# ESP32-S31 register map
Vendor: ESPRESSIF SYSTEMS (SHANGHAI) CO., LTD.; Series: ESP32 S-Series; File version: 1
CPU: RV32IMAFC r0p0, little endian, no MPU, FPU, 0 interrupt priority bits
Address unit: 32 bits
Registers are 32-bit, read-write, reset 0x0 unless marked. A register's access mark holds for its fields unless they carry their own. Offsets are from the block's base; [hi:lo] are bit positions; {n}, {i} and the like mark numbered series.

## LP_TOUCH_AON — LP_TOUCH_AON Peripheral
Base 0x20705000
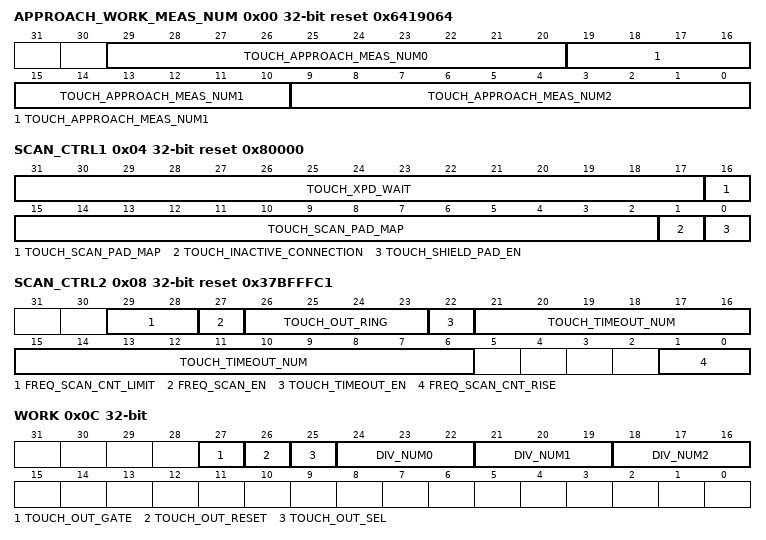
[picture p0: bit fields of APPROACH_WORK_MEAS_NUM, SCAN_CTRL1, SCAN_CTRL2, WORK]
0x00 APPROACH_WORK_MEAS_NUM reset 0x6419064 — need_des
  [29:20] TOUCH_APPROACH_MEAS_NUM0 — need_des
  [19:10] TOUCH_APPROACH_MEAS_NUM1 — need_des
  [9:0] TOUCH_APPROACH_MEAS_NUM2 — need_des
0x04 SCAN_CTRL1 reset 0x80000 — need_des
  [31:17] TOUCH_XPD_WAIT — need_des
  [16:2] TOUCH_SCAN_PAD_MAP — need_des
  [1] TOUCH_INACTIVE_CONNECTION — need_des
  [0] TOUCH_SHIELD_PAD_EN — need_des
0x08 SCAN_CTRL2 reset 0x37BFFFC1 — need_des
  [29:28] FREQ_SCAN_CNT_LIMIT — need_des
  [27] FREQ_SCAN_EN — need_des
  [26:23] TOUCH_OUT_RING — need_des
  [22] TOUCH_TIMEOUT_EN — need_des
  [21:6] TOUCH_TIMEOUT_NUM — need_des
  [1:0] FREQ_SCAN_CNT_RISE — need_des
0x0C WORK access per field — need_des
  [27] TOUCH_OUT_GATE rw — need_des
  [26] TOUCH_OUT_RESET wo — need_des
  [25] TOUCH_OUT_SEL rw — need_des
  [24:22] DIV_NUM0 rw — need_des
  [21:19] DIV_NUM1 rw — need_des
  [18:16] DIV_NUM2 rw — need_des
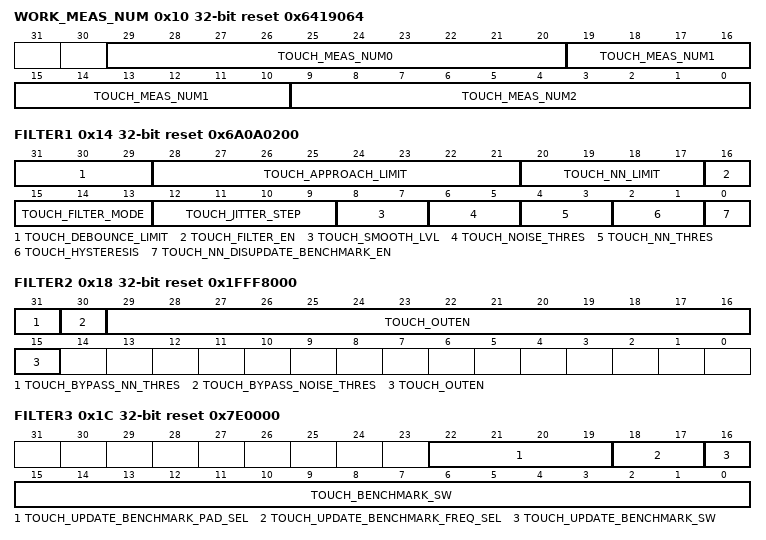
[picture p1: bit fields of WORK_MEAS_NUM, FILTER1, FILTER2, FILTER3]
0x10 WORK_MEAS_NUM reset 0x6419064 — need_des
  [29:20] TOUCH_MEAS_NUM0 — need_des
  [19:10] TOUCH_MEAS_NUM1 — need_des
  [9:0] TOUCH_MEAS_NUM2 — need_des
0x14 FILTER1 reset 0x6A0A0200 — need_des
  [31:29] TOUCH_DEBOUNCE_LIMIT — need_des
  [28:21] TOUCH_APPROACH_LIMIT — need_des
  [20:17] TOUCH_NN_LIMIT — need_des
  [16] TOUCH_FILTER_EN — need_des
  [15:13] TOUCH_FILTER_MODE — need_des
  [12:9] TOUCH_JITTER_STEP — need_des
  [8:7] TOUCH_SMOOTH_LVL — need_des
  [6:5] TOUCH_NOISE_THRES — need_des
  [4:3] TOUCH_NN_THRES — need_des
  [2:1] TOUCH_HYSTERESIS — need_des
  [0] TOUCH_NN_DISUPDATE_BENCHMARK_EN — Reserved
0x18 FILTER2 reset 0x1FFF8000 — need_des
  [31] TOUCH_BYPASS_NN_THRES — need_des
  [30] TOUCH_BYPASS_NOISE_THRES — need_des
  [29:15] TOUCH_OUTEN — need_des
0x1C FILTER3 access per field reset 0x7E0000 — need_des
  [22:19] TOUCH_UPDATE_BENCHMARK_PAD_SEL rw — Reserved
  [18:17] TOUCH_UPDATE_BENCHMARK_FREQ_SEL rw — Reserved
  [16] TOUCH_UPDATE_BENCHMARK_SW wo — need_des
  [15:0] TOUCH_BENCHMARK_SW rw — need_des
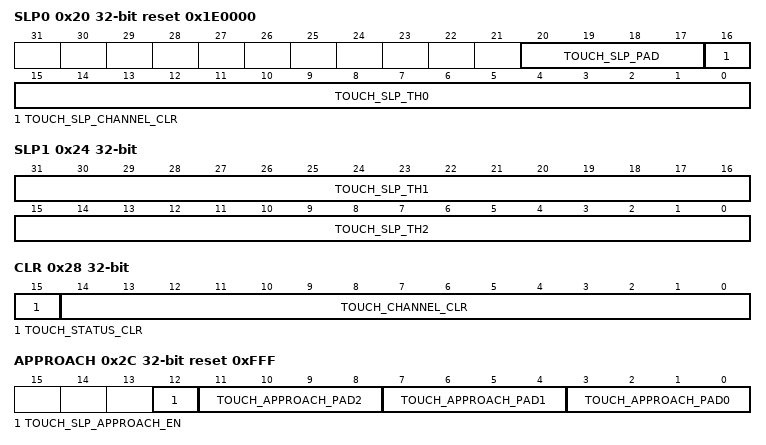
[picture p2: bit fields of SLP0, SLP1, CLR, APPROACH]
0x20 SLP0 access per field reset 0x1E0000 — need_des
  [20:17] TOUCH_SLP_PAD rw — need_des
  [16] TOUCH_SLP_CHANNEL_CLR wo — need_des
  [15:0] TOUCH_SLP_TH0 rw — need_des
0x24 SLP1 — need_des
  [31:16] TOUCH_SLP_TH1 — need_des
  [15:0] TOUCH_SLP_TH2 — need_des
0x28 CLR wo — need_des
  [15] TOUCH_STATUS_CLR — need_des
  [14:0] TOUCH_CHANNEL_CLR — need_des
0x2C APPROACH reset 0xFFF — need_des
  [12] TOUCH_SLP_APPROACH_EN — need_des
  [11:8] TOUCH_APPROACH_PAD2 — need_des
  [7:4] TOUCH_APPROACH_PAD1 — need_des
  [3:0] TOUCH_APPROACH_PAD0 — need_des
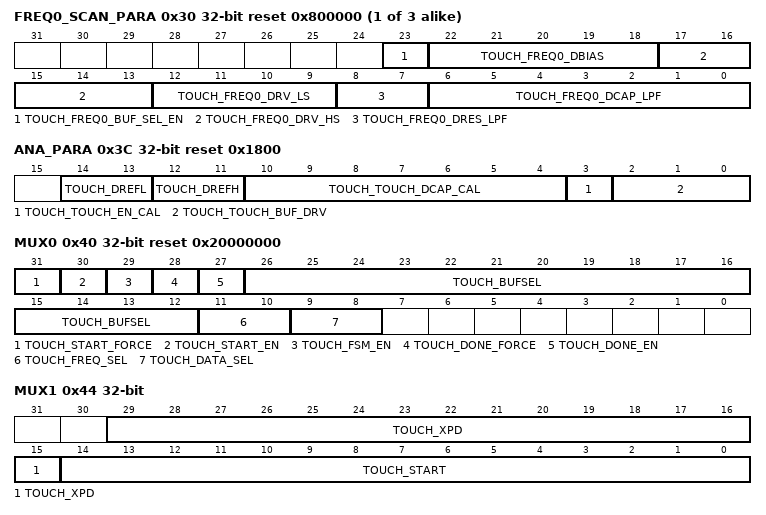
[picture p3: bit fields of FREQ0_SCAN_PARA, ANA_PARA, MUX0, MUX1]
{0x30+4i} FREQ{i}_SCAN_PARA reset 0x800000 (i=0..2) — need_des
  [23] TOUCH_FREQ{i}_BUF_SEL_EN — need_des
  [22:18] TOUCH_FREQ{i}_DBIAS — need_des
  [17:13] TOUCH_FREQ{i}_DRV_HS — need_des
  [12:9] TOUCH_FREQ{i}_DRV_LS — need_des
  [8:7] TOUCH_FREQ{i}_DRES_LPF — need_des
  [6:0] TOUCH_FREQ{i}_DCAP_LPF — need_des
0x3C ANA_PARA reset 0x1800 — need_des
  [14:13] TOUCH_DREFL — need_des
  [12:11] TOUCH_DREFH — need_des
  [10:4] TOUCH_TOUCH_DCAP_CAL — need_des
  [3] TOUCH_TOUCH_EN_CAL — need_des
  [2:0] TOUCH_TOUCH_BUF_DRV — need_des
0x40 MUX0 reset 0x20000000 — need_des
  [31] TOUCH_START_FORCE — need_des
  [30] TOUCH_START_EN — need_des
  [29] TOUCH_FSM_EN — need_des
  [28] TOUCH_DONE_FORCE — need_des
  [27] TOUCH_DONE_EN — need_des
  [26:12] TOUCH_BUFSEL — need_des
  [11:10] TOUCH_FREQ_SEL — need_des
  [9:8] TOUCH_DATA_SEL — need_des
0x44 MUX1 — need_des
  [29:15] TOUCH_XPD — need_des
  [14:0] TOUCH_START — need_des
{0x48+0xC*i} PAD{i}_TH0 (i=0..14) — need_des
  [31:16] TOUCH_PAD{i}_TH0 — Reserved
{0x4C+0xC*i} PAD{i}_TH1 (i=0..14) — need_des
  [31:16] TOUCH_PAD{i}_TH1 — Reserved
{0x50+0xC*i} PAD{i}_TH2 (i=0..14) — need_des
  [31:16] TOUCH_PAD{i}_TH2 — Reserved
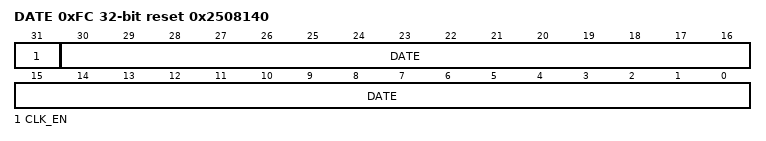
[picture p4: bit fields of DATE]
0xFC DATE reset 0x2508140 — need_des
  [31] CLK_EN — need_des
  [30:0] DATE — need_des
